AUTOSAR XML (schema 4-2-2)
package /STELLANTIS/EPT/ASWCs
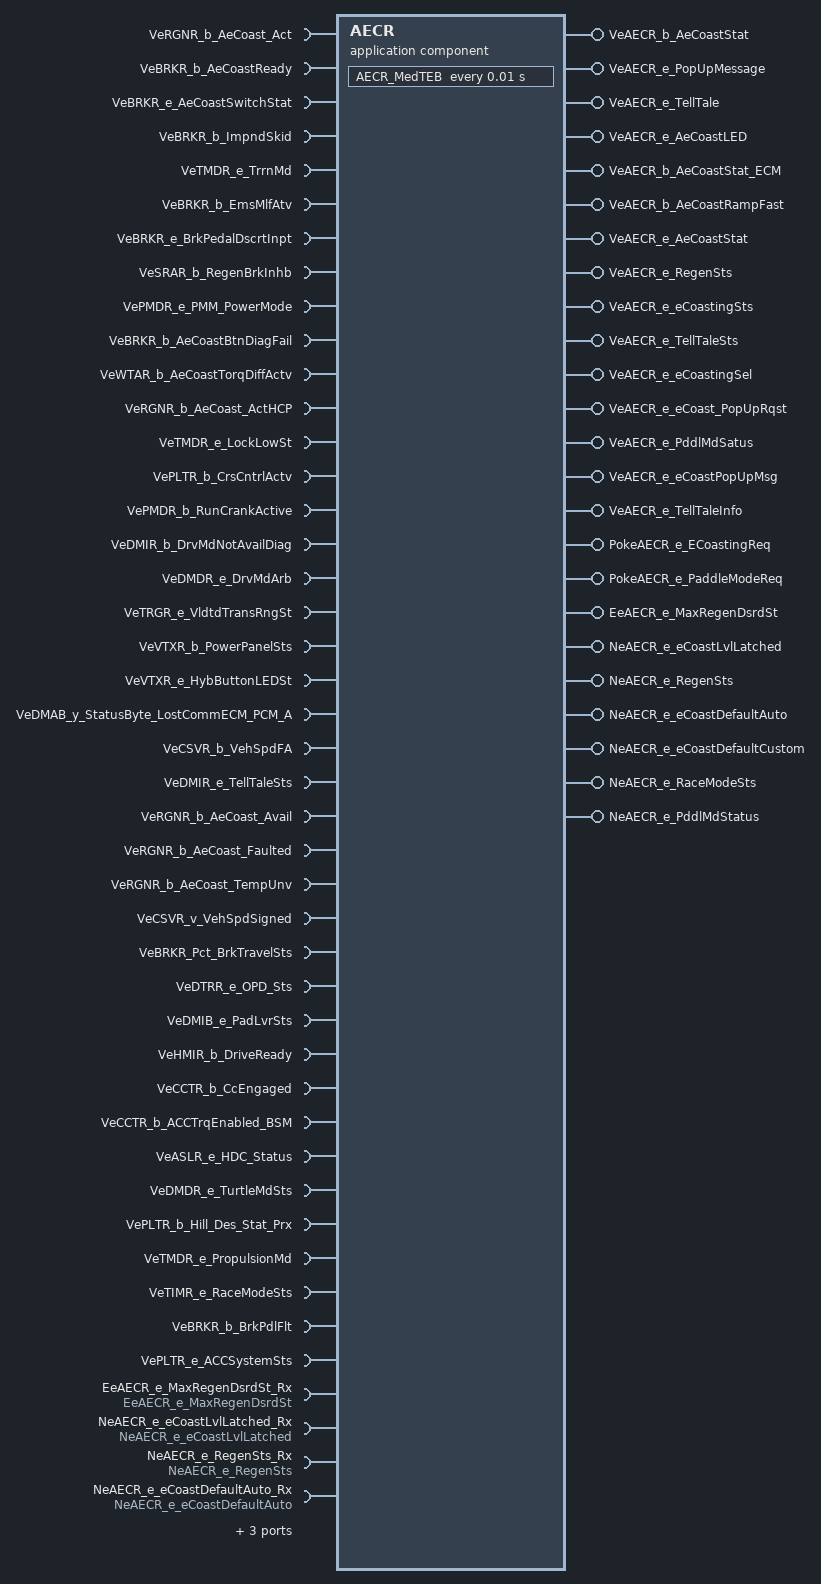
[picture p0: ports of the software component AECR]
  application sw component type AECR
    40 x require port:
      VeRGNR_b_AeCoast_Act: nonqueued-receiver-com-spec{data-element=Value, init-value=0}, required-interface=VeRGNR_b_AeCoast_Act
      VeBRKR_b_AeCoastReady: nonqueued-receiver-com-spec{data-element=Value, init-value=0}, required-interface=VeBRKR_b_AeCoastReady
      VeBRKR_e_AeCoastSwitchStat: nonqueued-receiver-com-spec{data-element=Value, init-value=CeBRKR_e_Button_Unpressed}, required-interface=VeBRKR_e_AeCoastSwitchStat
      VeBRKR_b_ImpndSkid: nonqueued-receiver-com-spec{data-element=Value, init-value=0}, required-interface=VeBRKR_b_ImpndSkid
      VeTMDR_e_TrrnMd: nonqueued-receiver-com-spec{data-element=Value, init-value=CeTMDR_e_NotDefine}, required-interface=VeTMDR_e_TrrnMd
      VeBRKR_b_EmsMlfAtv: nonqueued-receiver-com-spec{data-element=Value, init-value=0}, required-interface=VeBRKR_b_EmsMlfAtv
      VeBRKR_e_BrkPedalDscrtInpt: nonqueued-receiver-com-spec{data-element=Value, init-value=CeBRKR_e_BrkNotApplied}, required-interface=VeBRKR_e_BrkPedalDscrtInpt
      VeSRAR_b_RegenBrkInhb: nonqueued-receiver-com-spec{data-element=Value, init-value=0}, required-interface=VeSRAR_b_RegenBrkInhb
      VePMDR_e_PMM_PowerMode: nonqueued-receiver-com-spec{data-element=Value, init-value=CePMDR_e_PowerMode_Off}, required-interface=VePMDR_e_PMM_PowerMode
      VeBRKR_b_AeCoastBtnDiagFail: nonqueued-receiver-com-spec{data-element=Value, init-value=0}, required-interface=VeBRKR_b_AeCoastBtnDiagFail
      VeWTAR_b_AeCoastTorqDiffActv: nonqueued-receiver-com-spec{data-element=Value, init-value=0}, required-interface=VeWTAR_b_AeCoastTorqDiffActv
      VeRGNR_b_AeCoast_ActHCP: nonqueued-receiver-com-spec{data-element=Value, init-value=0}, required-interface=VeRGNR_b_AeCoast_ActHCP
      VeTMDR_e_LockLowSt: nonqueued-receiver-com-spec{data-element=Value, init-value=CeTMDR_e_Off}, required-interface=VeTMDR_e_LockLowSt
      VePLTR_b_CrsCntrlActv: nonqueued-receiver-com-spec{data-element=Value, init-value=0}, required-interface=VePLTR_b_CrsCntrlActv
      VePMDR_b_RunCrankActive: nonqueued-receiver-com-spec{data-element=Value, init-value=0}, required-interface=VePMDR_b_RunCrankActive
      VeDMIR_b_DrvMdNotAvailDiag: nonqueued-receiver-com-spec{data-element=Value, init-value=0}, required-interface=VeDMIR_b_DrvMdNotAvailDiag
      VeDMDR_e_DrvMdArb: nonqueued-receiver-com-spec{data-element=Value, init-value=CeDMDR_e_NoDrvMd}, required-interface=VeDMDR_e_DrvMdArb
      VeTRGR_e_VldtdTransRngSt: nonqueued-receiver-com-spec{data-element=Value, init-value=CeTRGR_e_NoSelectionAvailable}, required-interface=VeTRGR_e_VldtdTransRngSt
      VeVTXR_b_PowerPanelSts: nonqueued-receiver-com-spec{data-element=Value, init-value=0}, required-interface=VeVTXR_b_PowerPanelSts
      VeVTXR_e_HybButtonLEDSt: nonqueued-receiver-com-spec{data-element=Value, init-value=CeAECR_e_LEDOff}, required-interface=VeVTXR_e_HybButtonLEDSt
      VeDMAB_y_StatusByte_LostCommECM_PCM_A: nonqueued-receiver-com-spec{data-element=Value, init-value=0}, required-interface=VeDMAB_y_StatusByte_LostCommECM_PCM_A
      VeCSVR_b_VehSpdFA: nonqueued-receiver-com-spec{data-element=Value, init-value=0}, required-interface=VeCSVR_b_VehSpdFA
      VeDMIR_e_TellTaleSts: nonqueued-receiver-com-spec{data-element=Value, init-value=CeDMIR_e_Level1Sts}, required-interface=VeDMIR_e_TellTaleSts
      VeRGNR_b_AeCoast_Avail: nonqueued-receiver-com-spec{data-element=Value, init-value=0}, required-interface=VeRGNR_b_AeCoast_Avail
      VeRGNR_b_AeCoast_Faulted: nonqueued-receiver-com-spec{data-element=Value, init-value=0}, required-interface=VeRGNR_b_AeCoast_Faulted
      VeRGNR_b_AeCoast_TempUnv: nonqueued-receiver-com-spec{data-element=Value, init-value=0}, required-interface=VeRGNR_b_AeCoast_TempUnv
      VeCSVR_v_VehSpdSigned: nonqueued-receiver-com-spec{data-element=Value, init-value=0}, required-interface=VeCSVR_v_VehSpdSigned
      VeBRKR_Pct_BrkTravelSts: nonqueued-receiver-com-spec{data-element=Value, init-value=0}, required-interface=VeBRKR_Pct_BrkTravelSts
      VeDTRR_e_OPD_Sts: nonqueued-receiver-com-spec{data-element=Value, init-value=CeDTRR_e_Available}, required-interface=VeDTRR_e_OPD_Sts
      VeDMIB_e_PadLvrSts: nonqueued-receiver-com-spec{data-element=Value, init-value=CeDMIR_e_Init}, required-interface=VeDMIB_e_PadLvrSts
      VeHMIR_b_DriveReady: nonqueued-receiver-com-spec{data-element=Value, init-value=0}, required-interface=VeHMIR_b_DriveReady
      VeCCTR_b_CcEngaged: nonqueued-receiver-com-spec{data-element=Value, init-value=0}, required-interface=VeCCTR_b_CcEngaged
      VeCCTR_b_ACCTrqEnabled_BSM: nonqueued-receiver-com-spec{data-element=Value, init-value=0}, required-interface=VeCCTR_b_ACCTrqEnabled_BSM
      VeASLR_e_HDC_Status: nonqueued-receiver-com-spec{data-element=Value, init-value=CeASLR_e_HDC_UNAVL}, required-interface=VeASLR_e_HDC_Status
      VeDMDR_e_TurtleMdSts: nonqueued-receiver-com-spec{data-element=Value, init-value=CeDMDR_e_No_Turtle_Mode}, required-interface=VeDMDR_e_TurtleMdSts
      VePLTR_b_Hill_Des_Stat_Prx: nonqueued-receiver-com-spec{data-element=Value, init-value=0}, required-interface=VePLTR_b_Hill_Des_Stat_Prx
      VeTMDR_e_PropulsionMd: nonqueued-receiver-com-spec{data-element=Value, init-value=CeTMDR_e_NotDefine}, required-interface=VeTMDR_e_PropulsionMd
      VeTIMR_e_RaceModeSts: nonqueued-receiver-com-spec{data-element=Value, init-value=CeTIMR_e_RaceMode_Off}, required-interface=VeTIMR_e_RaceModeSts
      VeBRKR_b_BrkPdlFlt: nonqueued-receiver-com-spec{data-element=Value, init-value=0}, required-interface=VeBRKR_b_BrkPdlFlt
      VePLTR_e_ACCSystemSts: nonqueued-receiver-com-spec{data-element=Value, init-value=CePLTR_e_Off}, required-interface=VePLTR_e_ACCSystemSts
    17 x provide port:
      VeAECR_b_AeCoastStat: nonqueued-sender-com-spec{data-element=Value, init-value=0}, provided-interface=VeAECR_b_AeCoastStat
      VeAECR_e_PopUpMessage: nonqueued-sender-com-spec{data-element=Value, init-value=CeAECR_e_MaxRegenOff}, provided-interface=VeAECR_e_PopUpMessage
      VeAECR_e_TellTale: nonqueued-sender-com-spec{data-element=Value, init-value=CeAECR_e_TelltaleOff}, provided-interface=VeAECR_e_TellTale
      VeAECR_e_AeCoastLED: nonqueued-sender-com-spec{data-element=Value, init-value=CeAECR_e_LEDOff}, provided-interface=VeAECR_e_AeCoastLED
      VeAECR_b_AeCoastStat_ECM: nonqueued-sender-com-spec{data-element=Value, init-value=0}, provided-interface=VeAECR_b_AeCoastStat_ECM
      VeAECR_b_AeCoastRampFast: nonqueued-sender-com-spec{data-element=Value, init-value=0}, provided-interface=VeAECR_b_AeCoastRampFast
      VeAECR_e_AeCoastStat: nonqueued-sender-com-spec{data-element=Value, init-value=CeAECR_e_AecoastingTemporarily_Unavailable}, provided-interface=VeAECR_e_AeCoastStat
      VeAECR_e_RegenSts: nonqueued-sender-com-spec{data-element=Value, init-value=CeDMIR_e_NormalRegen}, provided-interface=VeAECR_e_RegenSts
      VeAECR_e_eCoastingSts: nonqueued-sender-com-spec{data-element=Value, init-value=CeDMIR_e_NotAvailable}, provided-interface=VeAECR_e_eCoastingSts
      VeAECR_e_TellTaleSts: nonqueued-sender-com-spec{data-element=Value, init-value=CeDMIR_e_Level1Sts}, provided-interface=VeAECR_e_TellTaleSts
      VeAECR_e_eCoastingSel: nonqueued-sender-com-spec{data-element=Value, init-value=CeDMIR_e_Level1}, provided-interface=VeAECR_e_eCoastingSel
      VeAECR_e_eCoast_PopUpRqst: nonqueued-sender-com-spec{data-element=Value, init-value=CeDMIR_e_InfoLevel1}, provided-interface=VeAECR_e_eCoast_PopUpRqst
      VeAECR_e_PddlMdSatus: nonqueued-sender-com-spec{data-element=Value, init-value=CeDMIR_e_None}, provided-interface=VeAECR_e_PddlMdSatus
      VeAECR_e_eCoastPopUpMsg: nonqueued-sender-com-spec{data-element=Value, init-value=CeDMIR_e_Msg0}, provided-interface=VeAECR_e_eCoastPopUpMsg
      VeAECR_e_TellTaleInfo: nonqueued-sender-com-spec{data-element=Value, init-value=CeDMIR_e_InfoLevel1}, provided-interface=VeAECR_e_TellTaleInfo
      PokeAECR_e_ECoastingReq: server-com-spec{operation=PokeAECR_e_ECoastingReq, queue-length=1}, provided-interface=PokeAECR_e_ECoastingReq
      PokeAECR_e_PaddleModeReq: server-com-spec{operation=PokeAECR_e_PaddleModeReq, queue-length=1}, provided-interface=PokeAECR_e_PaddleModeReq
    7 x require port:
      EeAECR_e_MaxRegenDsrdSt_Rx: nv-require-com-spec{init-value=0, variable=EeAECR_e_MaxRegenDsrdSt}, required-interface=EeAECR_e_MaxRegenDsrdSt
      NeAECR_e_eCoastLvlLatched_Rx: nv-require-com-spec{init-value=CeDMIR_e_NotAvail, variable=NeAECR_e_eCoastLvlLatched}, required-interface=NeAECR_e_eCoastLvlLatched
      NeAECR_e_RegenSts_Rx: nv-require-com-spec{init-value=CeDMIR_e_NormalRegen, variable=NeAECR_e_RegenSts}, required-interface=NeAECR_e_RegenSts
      NeAECR_e_eCoastDefaultAuto_Rx: nv-require-com-spec{init-value=CeDMIR_e_Level1, variable=NeAECR_e_eCoastDefaultAuto}, required-interface=NeAECR_e_eCoastDefaultAuto
      NeAECR_e_eCoastDefaultCustom_Rx: nv-require-com-spec{init-value=CeDMIR_e_Level1, variable=NeAECR_e_eCoastDefaultCustom}, required-interface=NeAECR_e_eCoastDefaultCustom
      NeAECR_e_RaceModeSts_Rx: nv-require-com-spec{init-value=CeTIMR_e_RaceMode_Off, variable=NeAECR_e_RaceModeSts}, required-interface=NeAECR_e_RaceModeSts
      NeAECR_e_PddlMdStatus_Rx: nv-require-com-spec{init-value=CeDMIR_e_En, variable=NeAECR_e_PddlMdStatus}, required-interface=NeAECR_e_PddlMdStatus
    7 x provide port:
      EeAECR_e_MaxRegenDsrdSt: nv-provide-com-spec{ram-block-init-value=0, variable=EeAECR_e_MaxRegenDsrdSt}, provided-interface=EeAECR_e_MaxRegenDsrdSt
      NeAECR_e_eCoastLvlLatched: nv-provide-com-spec{ram-block-init-value=CeDMIR_e_NotAvail, variable=NeAECR_e_eCoastLvlLatched}, provided-interface=NeAECR_e_eCoastLvlLatched
      NeAECR_e_RegenSts: nv-provide-com-spec{ram-block-init-value=CeDMIR_e_NormalRegen, variable=NeAECR_e_RegenSts}, provided-interface=NeAECR_e_RegenSts
      NeAECR_e_eCoastDefaultAuto: nv-provide-com-spec{ram-block-init-value=CeDMIR_e_Level1, variable=NeAECR_e_eCoastDefaultAuto}, provided-interface=NeAECR_e_eCoastDefaultAuto
      NeAECR_e_eCoastDefaultCustom: nv-provide-com-spec{ram-block-init-value=CeDMIR_e_Level1, variable=NeAECR_e_eCoastDefaultCustom}, provided-interface=NeAECR_e_eCoastDefaultCustom
      NeAECR_e_RaceModeSts: nv-provide-com-spec{ram-block-init-value=CeTIMR_e_RaceMode_Off, variable=NeAECR_e_RaceModeSts}, provided-interface=NeAECR_e_RaceModeSts
      NeAECR_e_PddlMdStatus: nv-provide-com-spec{ram-block-init-value=CeDMIR_e_En, variable=NeAECR_e_PddlMdStatus}, provided-interface=NeAECR_e_PddlMdStatus
    behavior IB_AECR: data-type-mapping=msADTtoIDTMapping, handle-termination-and-restart=NO-SUPPORT, included-data-type-set=data-type=[TeAECR_e_AeCoastSt, TeAECR_e_MaxRegenDsrdSt]
      timing event Event_MedTEB: start-on-event=AECR_MedTEB, period=0.01
      operation invoked event Event_PokeAECR_e_ECoastingReq: start-on-event=PokeAECR_e_ECoastingReq, operation=PokeAECR_e_ECoastingReq.PokeAECR_e_ECoastingReq
      operation invoked event Event_PokeAECR_e_PaddleModeReq: start-on-event=PokeAECR_e_PaddleModeReq, operation=PokeAECR_e_PaddleModeReq.PokeAECR_e_PaddleModeReq
      init event Event_AECR_ac_Init: start-on-event=AECR_ac_Init
      init event Event_PwrOn: start-on-event=AECR_PwrOn
      init event Event_PwrOff: start-on-event=AECR_PwrOff
      explicit-inter-runnable-variables:
        data VeAECR_e_ECoastingReq_OutInit_IRV: category=VALUE, sw-calibration-access=READ-ONLY, type=TeDMIR_e_ECoastingReq, init-value=CeDMIR_e_LevelOne
        data VeAECR_e_PddlMdReq_OutInit_IRV: category=VALUE, sw-calibration-access=READ-ONLY, type=TeDMIR_e_PaddleModeRequest, init-value=CeDMIR_e_None
      6 x runnable:
        AECR_ac_Init
          data-send-points:
            15 x access:
              OUT_VeAECR_e_PopUpMessage_Value: accessed-variable=VeAECR_e_PopUpMessage.Value
              OUT_VeAECR_e_TellTale_Value: accessed-variable=VeAECR_e_TellTale.Value
              OUT_VeAECR_e_AeCoastLED_Value: accessed-variable=VeAECR_e_AeCoastLED.Value
              OUT_VeAECR_e_AeCoastStat_Value: accessed-variable=VeAECR_e_AeCoastStat.Value
              OUT_VeAECR_e_RegenSts_Value: accessed-variable=VeAECR_e_RegenSts.Value
              OUT_VeAECR_e_eCoastingSts_Value: accessed-variable=VeAECR_e_eCoastingSts.Value
              OUT_VeAECR_e_TellTaleSts_Value: accessed-variable=VeAECR_e_TellTaleSts.Value
              OUT_VeAECR_e_eCoastingSel_Value: accessed-variable=VeAECR_e_eCoastingSel.Value
              OUT_VeAECR_e_eCoast_PopUpRqst_Value: accessed-variable=VeAECR_e_eCoast_PopUpRqst.Value
              OUT_VeAECR_e_PddlMdSatus_Value: accessed-variable=VeAECR_e_PddlMdSatus.Value
              OUT_VeAECR_e_eCoastPopUpMsg_Value: accessed-variable=VeAECR_e_eCoastPopUpMsg.Value
              OUT_VeAECR_e_TellTaleInfo_Value: accessed-variable=VeAECR_e_TellTaleInfo.Value
              OUT_NeAECR_e_eCoastLvlLatched_NeAECR_e_eCoastLvlLatched: accessed-variable=NeAECR_e_eCoastLvlLatched.NeAECR_e_eCoastLvlLatched
              OUT_NeAECR_e_eCoastDefaultAuto_NeAECR_e_eCoastDefaultAuto: accessed-variable=NeAECR_e_eCoastDefaultAuto.NeAECR_e_eCoastDefaultAuto
              OUT_NeAECR_e_eCoastDefaultCustom_NeAECR_e_eCoastDefaultCustom: accessed-variable=NeAECR_e_eCoastDefaultCustom.NeAECR_e_eCoastDefaultCustom
        AECR_PwrOn
          data-receive-point-by-arguments:
            7 x access:
              IN_EeAECR_e_MaxRegenDsrdSt_Rx_EeAECR_e_MaxRegenDsrdSt: accessed-variable=EeAECR_e_MaxRegenDsrdSt_Rx.EeAECR_e_MaxRegenDsrdSt
              IN_NeAECR_e_PddlMdStatus_Rx_NeAECR_e_PddlMdStatus: accessed-variable=NeAECR_e_PddlMdStatus_Rx.NeAECR_e_PddlMdStatus
              IN_NeAECR_e_RaceModeSts_Rx_NeAECR_e_RaceModeSts: accessed-variable=NeAECR_e_RaceModeSts_Rx.NeAECR_e_RaceModeSts
              IN_NeAECR_e_RegenSts_Rx_NeAECR_e_RegenSts: accessed-variable=NeAECR_e_RegenSts_Rx.NeAECR_e_RegenSts
              IN_NeAECR_e_eCoastDefaultAuto_Rx_NeAECR_e_eCoastDefaultAuto: accessed-variable=NeAECR_e_eCoastDefaultAuto_Rx.NeAECR_e_eCoastDefaultAuto
              IN_NeAECR_e_eCoastDefaultCustom_Rx_NeAECR_e_eCoastDefaultCustom: accessed-variable=NeAECR_e_eCoastDefaultCustom_Rx.NeAECR_e_eCoastDefaultCustom
              IN_NeAECR_e_eCoastLvlLatched_Rx_NeAECR_e_eCoastLvlLatched: accessed-variable=NeAECR_e_eCoastLvlLatched_Rx.NeAECR_e_eCoastLvlLatched
          data-send-points:
            15 x access:
              OUT_VeAECR_e_PopUpMessage_Value: accessed-variable=VeAECR_e_PopUpMessage.Value
              OUT_VeAECR_b_AeCoastStat_ECM_Value: accessed-variable=VeAECR_b_AeCoastStat_ECM.Value
              OUT_VeAECR_b_AeCoastRampFast_Value: accessed-variable=VeAECR_b_AeCoastRampFast.Value
              OUT_VeAECR_e_TellTale_Value: accessed-variable=VeAECR_e_TellTale.Value
              OUT_VeAECR_b_AeCoastStat_Value: accessed-variable=VeAECR_b_AeCoastStat.Value
              OUT_VeAECR_e_AeCoastLED_Value: accessed-variable=VeAECR_e_AeCoastLED.Value
              OUT_VeAECR_e_AeCoastStat_Value: accessed-variable=VeAECR_e_AeCoastStat.Value
              OUT_VeAECR_e_RegenSts_Value: accessed-variable=VeAECR_e_RegenSts.Value
              OUT_VeAECR_e_eCoastingSts_Value: accessed-variable=VeAECR_e_eCoastingSts.Value
              OUT_VeAECR_e_TellTaleSts_Value: accessed-variable=VeAECR_e_TellTaleSts.Value
              OUT_VeAECR_e_eCoastingSel_Value: accessed-variable=VeAECR_e_eCoastingSel.Value
              OUT_VeAECR_e_eCoast_PopUpRqst_Value: accessed-variable=VeAECR_e_eCoast_PopUpRqst.Value
              OUT_VeAECR_e_PddlMdSatus_Value: accessed-variable=VeAECR_e_PddlMdSatus.Value
              OUT_VeAECR_e_eCoastPopUpMsg_Value: accessed-variable=VeAECR_e_eCoastPopUpMsg.Value
              OUT_VeAECR_e_TellTaleInfo_Value: accessed-variable=VeAECR_e_TellTaleInfo.Value
          written-local-variables:
            access WV_VeAECR_e_ECoastingReq_OutInit_IRV: accessed-variable=VeAECR_e_ECoastingReq_OutInit_IRV
            access WV_VeAECR_e_PddlMdReq_OutInit_IRV: accessed-variable=VeAECR_e_PddlMdReq_OutInit_IRV
        AECR_MedTEB
          data-receive-point-by-arguments:
            40 x access:
              IN_VeASLR_e_HDC_Status_Value: accessed-variable=VeASLR_e_HDC_Status.Value
              IN_VeBRKR_Pct_BrkTravelSts_Value: accessed-variable=VeBRKR_Pct_BrkTravelSts.Value
              IN_VeBRKR_b_AeCoastBtnDiagFail_Value: accessed-variable=VeBRKR_b_AeCoastBtnDiagFail.Value
              IN_VeBRKR_b_AeCoastReady_Value: accessed-variable=VeBRKR_b_AeCoastReady.Value
              IN_VeBRKR_b_BrkPdlFlt_Value: accessed-variable=VeBRKR_b_BrkPdlFlt.Value
              IN_VeBRKR_b_EmsMlfAtv_Value: accessed-variable=VeBRKR_b_EmsMlfAtv.Value
              IN_VeBRKR_b_ImpndSkid_Value: accessed-variable=VeBRKR_b_ImpndSkid.Value
              IN_VeBRKR_e_AeCoastSwitchStat_Value: accessed-variable=VeBRKR_e_AeCoastSwitchStat.Value
              IN_VeBRKR_e_BrkPedalDscrtInpt_Value: accessed-variable=VeBRKR_e_BrkPedalDscrtInpt.Value
              IN_VeCCTR_b_ACCTrqEnabled_BSM_Value: accessed-variable=VeCCTR_b_ACCTrqEnabled_BSM.Value
              IN_VeCCTR_b_CcEngaged_Value: accessed-variable=VeCCTR_b_CcEngaged.Value
              IN_VeCSVR_b_VehSpdFA_Value: accessed-variable=VeCSVR_b_VehSpdFA.Value
              IN_VeCSVR_v_VehSpdSigned_Value: accessed-variable=VeCSVR_v_VehSpdSigned.Value
              IN_VeDMAB_y_StatusByte_LostCommECM_PCM_A_Value: accessed-variable=VeDMAB_y_StatusByte_LostCommECM_PCM_A.Value
              IN_VeDMDR_e_DrvMdArb_Value: accessed-variable=VeDMDR_e_DrvMdArb.Value
              IN_VeDMDR_e_TurtleMdSts_Value: accessed-variable=VeDMDR_e_TurtleMdSts.Value
              IN_VeDMIB_e_PadLvrSts_Value: accessed-variable=VeDMIB_e_PadLvrSts.Value
              IN_VeDMIR_b_DrvMdNotAvailDiag_Value: accessed-variable=VeDMIR_b_DrvMdNotAvailDiag.Value
              IN_VeDMIR_e_TellTaleSts_Value: accessed-variable=VeDMIR_e_TellTaleSts.Value
              IN_VeDTRR_e_OPD_Sts_Value: accessed-variable=VeDTRR_e_OPD_Sts.Value
              IN_VeHMIR_b_DriveReady_Value: accessed-variable=VeHMIR_b_DriveReady.Value
              IN_VePLTR_b_CrsCntrlActv_Value: accessed-variable=VePLTR_b_CrsCntrlActv.Value
              IN_VePLTR_b_Hill_Des_Stat_Prx_Value: accessed-variable=VePLTR_b_Hill_Des_Stat_Prx.Value
              IN_VePLTR_e_ACCSystemSts_Value: accessed-variable=VePLTR_e_ACCSystemSts.Value
              IN_VePMDR_b_RunCrankActive_Value: accessed-variable=VePMDR_b_RunCrankActive.Value
              IN_VePMDR_e_PMM_PowerMode_Value: accessed-variable=VePMDR_e_PMM_PowerMode.Value
              IN_VeRGNR_b_AeCoast_Act_Value: accessed-variable=VeRGNR_b_AeCoast_Act.Value
              IN_VeRGNR_b_AeCoast_ActHCP_Value: accessed-variable=VeRGNR_b_AeCoast_ActHCP.Value
              IN_VeRGNR_b_AeCoast_Avail_Value: accessed-variable=VeRGNR_b_AeCoast_Avail.Value
              IN_VeRGNR_b_AeCoast_Faulted_Value: accessed-variable=VeRGNR_b_AeCoast_Faulted.Value
              IN_VeRGNR_b_AeCoast_TempUnv_Value: accessed-variable=VeRGNR_b_AeCoast_TempUnv.Value
              IN_VeSRAR_b_RegenBrkInhb_Value: accessed-variable=VeSRAR_b_RegenBrkInhb.Value
              IN_VeTIMR_e_RaceModeSts_Value: accessed-variable=VeTIMR_e_RaceModeSts.Value
              IN_VeTMDR_e_LockLowSt_Value: accessed-variable=VeTMDR_e_LockLowSt.Value
              IN_VeTMDR_e_PropulsionMd_Value: accessed-variable=VeTMDR_e_PropulsionMd.Value
              IN_VeTMDR_e_TrrnMd_Value: accessed-variable=VeTMDR_e_TrrnMd.Value
              IN_VeTRGR_e_VldtdTransRngSt_Value: accessed-variable=VeTRGR_e_VldtdTransRngSt.Value
              IN_VeVTXR_b_PowerPanelSts_Value: accessed-variable=VeVTXR_b_PowerPanelSts.Value
              IN_VeVTXR_e_HybButtonLEDSt_Value: accessed-variable=VeVTXR_e_HybButtonLEDSt.Value
              IN_VeWTAR_b_AeCoastTorqDiffActv_Value: accessed-variable=VeWTAR_b_AeCoastTorqDiffActv.Value
          data-send-points:
            15 x access:
              OUT_VeAECR_e_PopUpMessage_Value: accessed-variable=VeAECR_e_PopUpMessage.Value
              OUT_VeAECR_b_AeCoastStat_ECM_Value: accessed-variable=VeAECR_b_AeCoastStat_ECM.Value
              OUT_VeAECR_b_AeCoastRampFast_Value: accessed-variable=VeAECR_b_AeCoastRampFast.Value
              OUT_VeAECR_e_TellTale_Value: accessed-variable=VeAECR_e_TellTale.Value
              OUT_VeAECR_b_AeCoastStat_Value: accessed-variable=VeAECR_b_AeCoastStat.Value
              OUT_VeAECR_e_AeCoastLED_Value: accessed-variable=VeAECR_e_AeCoastLED.Value
              OUT_VeAECR_e_AeCoastStat_Value: accessed-variable=VeAECR_e_AeCoastStat.Value
              OUT_VeAECR_e_RegenSts_Value: accessed-variable=VeAECR_e_RegenSts.Value
              OUT_VeAECR_e_eCoastingSts_Value: accessed-variable=VeAECR_e_eCoastingSts.Value
              OUT_VeAECR_e_TellTaleSts_Value: accessed-variable=VeAECR_e_TellTaleSts.Value
              OUT_VeAECR_e_TellTaleInfo_Value: accessed-variable=VeAECR_e_TellTaleInfo.Value
              OUT_VeAECR_e_eCoast_PopUpRqst_Value: accessed-variable=VeAECR_e_eCoast_PopUpRqst.Value
              OUT_VeAECR_e_eCoastingSel_Value: accessed-variable=VeAECR_e_eCoastingSel.Value
              OUT_VeAECR_e_PddlMdSatus_Value: accessed-variable=VeAECR_e_PddlMdSatus.Value
              OUT_VeAECR_e_eCoastPopUpMsg_Value: accessed-variable=VeAECR_e_eCoastPopUpMsg.Value
          read-local-variables:
            access RV_VeAECR_e_ECoastingReq_OutInit_IRV: accessed-variable=VeAECR_e_ECoastingReq_OutInit_IRV
            access RV_VeAECR_e_PddlMdReq_OutInit_IRV: accessed-variable=VeAECR_e_PddlMdReq_OutInit_IRV
        AECR_PwrOff
          data-send-points:
            7 x access:
              OUT_EeAECR_e_MaxRegenDsrdSt_EeAECR_e_MaxRegenDsrdSt: accessed-variable=EeAECR_e_MaxRegenDsrdSt.EeAECR_e_MaxRegenDsrdSt
              OUT_NeAECR_e_eCoastLvlLatched_NeAECR_e_eCoastLvlLatched: accessed-variable=NeAECR_e_eCoastLvlLatched.NeAECR_e_eCoastLvlLatched
              OUT_NeAECR_e_RegenSts_NeAECR_e_RegenSts: accessed-variable=NeAECR_e_RegenSts.NeAECR_e_RegenSts
              OUT_NeAECR_e_eCoastDefaultAuto_NeAECR_e_eCoastDefaultAuto: accessed-variable=NeAECR_e_eCoastDefaultAuto.NeAECR_e_eCoastDefaultAuto
              OUT_NeAECR_e_eCoastDefaultCustom_NeAECR_e_eCoastDefaultCustom: accessed-variable=NeAECR_e_eCoastDefaultCustom.NeAECR_e_eCoastDefaultCustom
              OUT_NeAECR_e_RaceModeSts_NeAECR_e_RaceModeSts: accessed-variable=NeAECR_e_RaceModeSts.NeAECR_e_RaceModeSts
              OUT_NeAECR_e_PddlMdStatus_NeAECR_e_PddlMdStatus: accessed-variable=NeAECR_e_PddlMdStatus.NeAECR_e_PddlMdStatus
        PokeAECR_e_ECoastingReq
          written-local-variables:
            access WV_VeAECR_e_ECoastingReq_OutInit_IRV: accessed-variable=VeAECR_e_ECoastingReq_OutInit_IRV
        PokeAECR_e_PaddleModeReq
          written-local-variables:
            access WV_VeAECR_e_PddlMdReq_OutInit_IRV: accessed-variable=VeAECR_e_PddlMdReq_OutInit_IRV
      variation point proxy Variant_AECR_1: category=CONDITION, condition-access=0
      variation point proxy Variant_AECR_2: category=CONDITION, condition-access=1
      variation point proxy Variant_AECR_3: category=CONDITION, condition-access=1
